# ATSAMD20J14B device description
Architecture: CORTEX-M0PLUS; Family: SAMD; Series: SAMD20
Registers are 8-bit, read-write, reset 0x0 unless marked. A register's access mark holds for its fields unless they carry their own. Offsets are from the block's base; [hi:lo] are bit positions; {n}, {i} and the like mark numbered series; 'fields as' and 'values as' point back to an identical list; <NAME> marks a mode.

## SERCOM — Serial Communication Interface
Instances: SERCOM{n} {0x42000800+0x400*n} (n=0..5)
Modes: I2CM when SERCOM.I2CM_CTRLA.MODE=5 (I2C Master Mode); I2CS when SERCOM.I2CS_CTRLA.MODE=4 (I2C Slave Mode); SPIS when SERCOM.SPIS_CTRLA.MODE=2 under mask 6 (SPI Slave Mode); SPIM when SERCOM.SPIM_CTRLA.MODE=3 under mask 6 (SPI Master Mode); USART_EXT when SERCOM.USART_CTRLA.MODE=0 under mask 6 (USART EXTERNAL CLOCK Mode); USART_INT when SERCOM.USART_CTRLA.MODE=1 under mask 6 (USART INTERNAL CLOCK Mode)
0x00 CTRLA <I2CM> 32-bit (WSYNC) — I2CM Control A
  [30] LOWTOUT — SCL Low Time-out
  [29:28] INACTOUT — Inactive Time-out
    0=DISABLE (Disabled); 1=55US (5-6 SCL Time-Out(50-60us)); 2=105US (10-11 SCL Time-Out(100-110us)); 3=205US (20-21 SCL Time-Out(200-210us))
  [21:20] SDAHOLD — SDA Hold Time
    0=DISABLE (Disabled); 1=75NS (50-100ns hold time); 2=450NS (300-600ns hold time); 3=600NS (400-800ns hold time)
  [16] PINOUT — Pin Usage
  [7] RUNSTDBY — Run in Standby
  [4:2] MODE — Operating Mode
    0=USART_EXT_CLK (USART with external clock); 1=USART_INT_CLK (USART with internal clock); 2=SPI_SLAVE (SPI in slave operation); 3=SPI_MASTER (SPI in master operation); 4=I2C_SLAVE (I2C slave operation); 5=I2C_MASTER (I2C master operation)
  [1] ENABLE
  [0] SWRST — Software Reset
0x04 CTRLB <I2CM> 32-bit (WSYNC) — I2CM Control B
  [18] ACKACT — Acknowledge Action
  [17:16] CMD — Command
  [9] QCEN — Quick Command Enable
  [8] SMEN — Smart Mode Enable
0x08 DBGCTRL <I2CM> — I2CM Debug Control
  [0] DBGSTOP — Debug Stop Mode
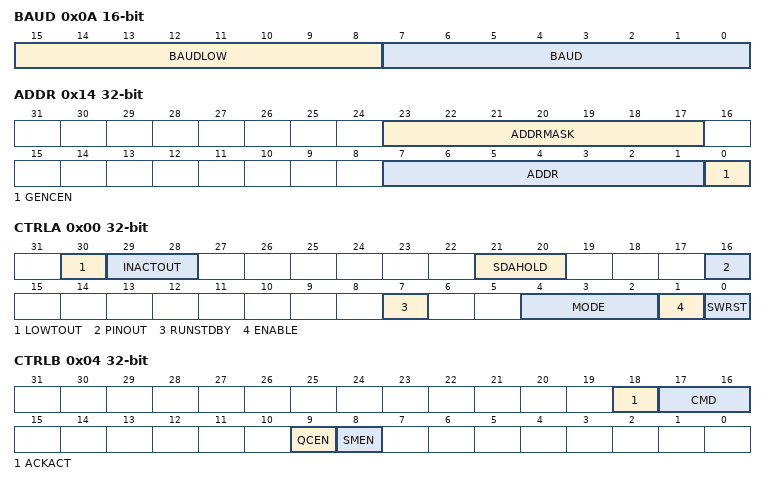
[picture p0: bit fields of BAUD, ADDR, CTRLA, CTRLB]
0x0A BAUD <I2CM> 16-bit — I2CM Baud Rate
  [15:8] BAUDLOW — Master Baud Rate Low
  [7:0] BAUD — Master Baud Rate
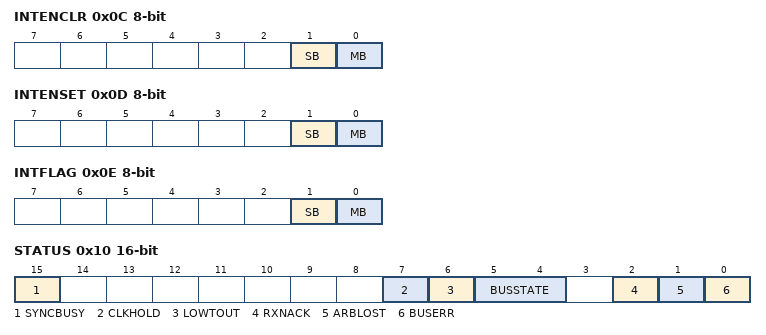
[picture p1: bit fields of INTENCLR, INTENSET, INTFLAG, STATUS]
0x0C INTENCLR <I2CM> (atomic clear) — I2CM Interrupt Enable Clear
  [1] SB — Slave on Bus Interrupt Enable
  [0] MB — Master on Bus Interrupt Enable
0x0D INTENSET <I2CM> (atomic set) — I2CM Interrupt Enable Set
  fields as INTENCLR<I2CM>
0x0E INTFLAG <I2CM> (atomic clear) — I2CM Interrupt Flag Status and Clear
  [1] SB — Slave on Bus
  [0] MB — Master on Bus
0x10 STATUS <I2CM> 16-bit (WSYNC) — I2CM Status
  [15] SYNCBUSY — Synchronization Busy
  [7] CLKHOLD — Clock Hold
  [6] LOWTOUT — SCL Low Time-out
  [5:4] BUSSTATE
  [2] RXNACK — Received Not Acknowledge
  [1] ARBLOST — Arbitration Lost
  [0] BUSERR — Bus Error
0x14 ADDR <I2CM> (WSYNC) — I2CM Address
  [7:0] ADDR — Address
0x18 DATA <I2CM> — I2CM Data
0x00 CTRLA <I2CS> 32-bit (WSYNC) — I2CS Control A
  [30] LOWTOUT — SCL Low Time-out
  [21:20] SDAHOLD — SDA Hold Time
    values as CTRLA<I2CM>.SDAHOLD
  [16] PINOUT — Pin Usage
  [7] RUNSTDBY — Run in Standby
  [4:2] MODE — Operating Mode
    values as CTRLA<I2CM>.MODE
  [1] ENABLE
  [0] SWRST — Software Reset
0x04 CTRLB <I2CS> 32-bit (WSYNC) — I2CS Control B
  [18] ACKACT — Acknowledge Action
  [17:16] CMD — Command
  [15:14] AMODE — Address Mode
  [8] SMEN — Smart Mode Enable
0x0C INTENCLR <I2CS> (atomic clear) — I2CS Interrupt Enable Clear
  [2] DRDY — Data Ready Interrupt Enable
  [1] AMATCH — Address Match Interrupt Enable
  [0] PREC — Stop Received Interrupt Enable
0x0D INTENSET <I2CS> (atomic set) — I2CS Interrupt Enable Set
  fields as INTENCLR<I2CS>
0x0E INTFLAG <I2CS> (atomic clear) — I2CS Interrupt Flag Status and Clear
  [2] DRDY — Data Ready
  [1] AMATCH — Address Match
  [0] PREC — Stop Received
0x10 STATUS <I2CS> 16-bit (WSYNC) — I2CS Status
  [15] SYNCBUSY — Synchronization Busy
  [7] CLKHOLD — Clock Hold
  [6] LOWTOUT — SCL Low Time-out
  [4] SR — Repeated Start
  [3] DIR — Read / Write Direction
  [2] RXNACK — Received Not Acknowledge
  [1] COLL — Transmit Collision
  [0] BUSERR — Bus Error
0x14 ADDR <I2CS> 32-bit — I2CS Address
  [23:17] ADDRMASK — Address Mask
  [7:1] ADDR — Address
  [0] GENCEN — General Call Address Enable
0x18 DATA <I2CS> — I2CS Data
0x00 CTRLA <SPIM> 32-bit (WSYNC) — SPIM Control A
  [30] DORD — Data Order
    0=MSB (MSB is transferred first); 1=LSB (LSB is transferred first)
  [29] CPOL — Clock Polarity
    0=IDLE_LOW (SCK is low when idle); 1=IDLE_HIGH (SCK is high when idle)
  [28] CPHA — Clock Phase
    0=LEADING_EDGE (The data is sampled on a leading SCK edge and changed on a trailing SCK edge); 1=TRAILING_EDGE (The data is sampled on a trailing SCK edge and changed on a leading SCK edge)
  [27:24] FORM — Frame Format
    0=SPI_FRAME; 2=SPI_FRAME_WITH_ADDR
  [21:20] DIPO — Data In Pinout
    {v}=PAD{v} (SERCOM PAD[{v}]) (v=0..3)
  [17:16] DOPO — Data Out Pinout
    0=PAD0 (DO on PAD[0], SCK on PAD[1] and SS on PAD[2]); 1=PAD1 (DO on PAD[2], SCK on PAD[3] and SS on PAD[1]); 2=PAD2 (DO on PAD[3], SCK on PAD[1] and SS on PAD[2]); 3=PAD3 (DO on PAD[0], SCK on PAD[3] and SS on PAD[1])
  [8] IBON — Immediate Buffer Overflow Notification
  [7] RUNSTDBY — Run In Standby
  [4:2] MODE — Operating Mode
    values as CTRLA<I2CM>.MODE
  [1] ENABLE
  [0] SWRST — Software Reset
0x04 CTRLB <SPIM> 32-bit — SPIM Control B
  [17] RXEN — Receiver Enable
  [15:14] AMODE — Address Mode
    0=MASK (ADDRMASK is used as a mask to the ADDR register.); 1=2_ADDRESSES (The slave responds to the 2 unique addresses in ADDR and ADDRMASK.); 2=RANGE (The slave responds to the range of addresses between and including ADDR and ADDRMASK. ADDR is the upper limit.)
  [6] PLOADEN — Slave Data Preload Enable
  [2:0] CHSIZE — Character Size
    0=8_BIT (8 bits); 1=9_BIT (9 bits)
0x08 DBGCTRL <SPIM> — SPIM Debug Control
  [0] DBGSTOP — Debug Stop Mode
0x0A BAUD <SPIM> — SPIM Baud Rate
0x0C INTENCLR <SPIM> (atomic clear) — SPIM Interrupt Enable Clear
  [2] RXC — Receive Complete Interrupt Enable
  [1] TXC — Transmit Complete Interrupt Enable
  [0] DRE — Data Register Empty Interrupt Enable
0x0D INTENSET <SPIM> (atomic set) — SPIM Interrupt Enable Set
  fields as INTENCLR<SPIM>
0x0E INTFLAG <SPIM> (atomic clear) — SPIM Interrupt Flag Status and Clear
  [2] RXC — Receive Complete
  [1] TXC — Transmit Complete
  [0] DRE — Data Register Empty
0x10 STATUS <SPIM> 16-bit — SPIM Status
  [15] SYNCBUSY — Synchronization Busy
  [2] BUFOVF — Buffer Overflow
0x14 ADDR <SPIM> 32-bit — SPIM Address
  [23:16] ADDRMASK — Address Mask
  [7:0] ADDR — Address
0x18 DATA <SPIM> 16-bit — SPIM Data
  [8:0] DATA
0x00 CTRLA <SPIS> 32-bit (WSYNC) — SPIS Control A
  fields as CTRLA<SPIM>
0x04 CTRLB <SPIS> 32-bit — SPIS Control B
  fields as CTRLB<SPIM>
0x08 DBGCTRL <SPIS> — SPIS Debug Control
  [0] DBGSTOP — Debug Stop Mode
0x0A BAUD <SPIS> — SPIS Baud Rate
0x0C INTENCLR <SPIS> (atomic clear) — SPIS Interrupt Enable Clear
  fields as INTENCLR<SPIM>
0x0D INTENSET <SPIS> (atomic set) — SPIS Interrupt Enable Set
  fields as INTENCLR<SPIM>
0x0E INTFLAG <SPIS> (atomic clear) — SPIS Interrupt Flag Status and Clear
  fields as INTFLAG<SPIM>
0x10 STATUS <SPIS> 16-bit — SPIS Status
  [15] SYNCBUSY — Synchronization Busy
  [2] BUFOVF — Buffer Overflow
0x14 ADDR <SPIS> 32-bit — SPIS Address
  [23:16] ADDRMASK — Address Mask
  [7:0] ADDR — Address
0x18 DATA <SPIS> 16-bit — SPIS Data
  [8:0] DATA — Data Value
0x00 CTRLA <USART_EXT> 32-bit (WSYNC) — USART_EXT Control A
  [30] DORD — Data Order
    0=MSB (MSB is transmitted first); 1=LSB (LSB is transmitted first)
  [29] CPOL — Clock Polarity
    0=IDLE_LOW (TxD Change:- Rising XCK edge, RxD Sample:- Falling XCK edge); 1=IDLE_HIGH (TxD Change:- Falling XCK edge, RxD Sample:- Rising XCK edge)
  [28] CMODE — Communication Mode
    0=ASYNC (Asynchronous Communication); 1=SYNC (Synchronous Communication)
  [27:24] FORM — Frame Format
    0=USART_FRAME_NO_PARITY; 1=USART_FRAME_WITH_PARITY
  [21:20] RXPO — Receive Data Pinout
    {v}=PAD{v} (SERCOM PAD[{v}] is used for data reception) (v=0..3)
  [16] TXPO — Transmit Data Pinout
    0=PAD0 (SERCOM PAD[0] is used for data transmission); 1=PAD2 (SERCOM PAD[2] is used for data transmission)
  [8] IBON — Immediate Buffer Overflow Notification
  [7] RUNSTDBY — Run In Standby
  [4:2] MODE — Operating Mode
    values as CTRLA<I2CM>.MODE
  [1] ENABLE
  [0] SWRST — Software Reset
0x04 CTRLB <USART_EXT> 32-bit (WSYNC) — USART_EXT Control B
  [17] RXEN — Receiver Enable
  [16] TXEN — Transmitter Enable
  [13] PMODE — Parity Mode
    0=EVEN (Even Parity); 1=ODD (Odd Parity)
  [9] SFDE — Start of Frame Detection Enable
  [6] SBMODE — Stop Bit Mode
    0=1_BIT (One Stop Bit); 1=2_BIT (Two Stop Bits)
  [2:0] CHSIZE — Character Size
    0=8_BIT (8 Bits); 1=9_BIT (9 Bits); 5=5_BIT (5 Bits); 6=6_BIT (6 Bits); 7=7_BIT (7 Bits)
0x08 DBGCTRL <USART_EXT> — USART_EXT Debug Control
  [0] DBGSTOP — Debug Stop Mode
0x0A BAUD <USART_EXT> 16-bit — USART_EXT Baud
  [15:0] BAUD — Baud Value
0x0C INTENCLR <USART_EXT> (atomic clear) — USART_EXT Interrupt Enable Clear
  [3] RXS — Receive Start Interrupt Disable
  [2] RXC — Receive Complete Interrupt Enable
  [1] TXC — Transmit Complete Interrupt Enable
  [0] DRE — Data Register Empty Interrupt Enable
0x0D INTENSET <USART_EXT> (atomic set) — USART_EXT Interrupt Enable Set
  [3] RXS — Receive Start Interrupt Enable
  [2] RXC — Receive Complete Interrupt Enable
  [1] TXC — Transmit Complete Interrupt Enable
  [0] DRE — Data Register Empty Interrupt Enable
0x0E INTFLAG <USART_EXT> (atomic clear) — USART_EXT Interrupt Flag Status and Clear
  [3] RXS — Receive Start Interrupt
  [2] RXC — Receive Complete
  [1] TXC — Transmit Complete
  [0] DRE — Data Register Empty
0x10 STATUS <USART_EXT> 16-bit — USART_EXT Status
  [15] SYNCBUSY — Synchronization Busy
  [2] BUFOVF — Buffer Overflow
  [1] FERR — Frame Error
  [0] PERR — Parity Error
0x18 DATA <USART_EXT> 16-bit — USART_EXT Data
  [8:0] DATA
0x00 CTRLA <USART_INT> 32-bit (WSYNC) — USART_INT Control A
  fields as CTRLA<USART_EXT>
0x04 CTRLB <USART_INT> 32-bit (WSYNC) — USART_INT Control B
  fields as CTRLB<USART_EXT>
0x08 DBGCTRL <USART_INT> — USART_INT Debug Control
  [0] DBGSTOP — Debug Stop Mode
0x0A BAUD <USART_INT> 16-bit — USART_INT Baud
  [15:0] BAUD — Baud Value
0x0C INTENCLR <USART_INT> (atomic clear) — USART_INT Interrupt Enable Clear
  fields as INTENCLR<USART_EXT>
0x0D INTENSET <USART_INT> (atomic set) — USART_INT Interrupt Enable Set
  fields as INTENSET<USART_EXT>
0x0E INTFLAG <USART_INT> (atomic clear) — USART_INT Interrupt Flag Status and Clear
  fields as INTFLAG<USART_EXT>
0x10 STATUS <USART_INT> 16-bit — USART_INT Status
  fields as STATUS<USART_EXT>
0x18 DATA <USART_INT> 16-bit — USART_INT Data
  [8:0] DATA

## Notices in the file
Copyright (c) 2018 Microchip Technology Inc.
SPDX-License-Identifier: Apache-2.0
Licensed under the Apache License, Version 2.0 (the "License");
you may not use this file except in compliance with the License.
You may obtain a copy of the License at
http://www.apache.org/licenses/LICENSE-2.0
Unless required by applicable law or agreed to in writing, software
distributed under the License is distributed on an "AS IS" BASIS,
WITHOUT WARRANTIES OR CONDITIONS OF ANY KIND, either express or implied.
See the License for the specific language governing permissions and
limitations under the License.
